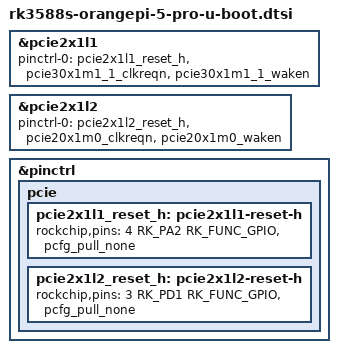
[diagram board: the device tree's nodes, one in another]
// SPDX-License-Identifier: (GPL-2.0+ OR MIT)

#include "rk3588s-u-boot.dtsi"

&pcie2x1l1 {
	pinctrl-0 = <&pcie2x1l1_reset_h>, <&pcie30x1m1_1_clkreqn>,
		    <&pcie30x1m1_1_waken>;
};

&pcie2x1l2 {
	pinctrl-0 = <&pcie2x1l2_reset_h>, <&pcie20x1m0_clkreqn>,
		    <&pcie20x1m0_waken>;
};

&pinctrl {
	pcie {
		pcie2x1l1_reset_h: pcie2x1l1-reset-h {
			rockchip,pins = <4 RK_PA2 RK_FUNC_GPIO &pcfg_pull_none>;
		};

		pcie2x1l2_reset_h: pcie2x1l2-reset-h {
			rockchip,pins = <3 RK_PD1 RK_FUNC_GPIO &pcfg_pull_none>;
		};
	};
};
